# STM32U385xx register map
File version: 1.0
Registers are 32-bit, read-write, reset 0x0 unless marked. A register's access mark holds for its fields unless they carry their own. Offsets are from the block's base; [hi:lo] are bit positions; {n}, {i} and the like mark numbered series; 'fields as' and 'values as' point back to an identical list.

## ICACHE — Instruction Cache
Base 0x40030400
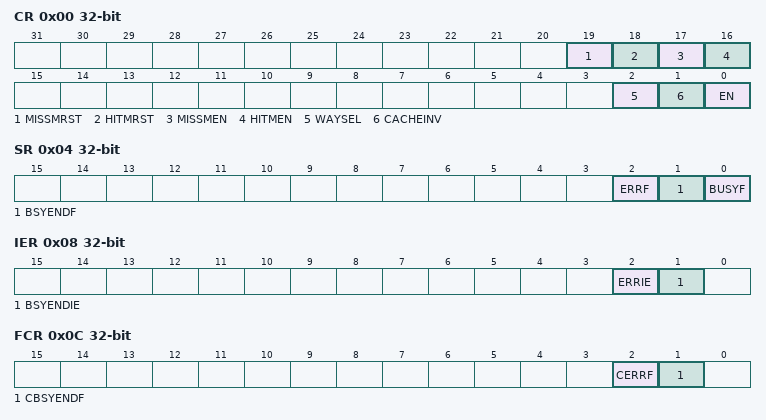
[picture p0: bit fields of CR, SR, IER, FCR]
0x00 CR — ICACHE control register
  [19] MISSMRST — Miss monitor reset
  [18] HITMRST — Hit monitor reset
  [17] MISSMEN — Miss monitor enable
  [16] HITMEN — Hit monitor enable
  [2] WAYSEL — Ways selection
    0=ICACHE_1WAY (1-way cache (direct mapped cache)); 1=ICACHE_2WAYS (2-ways set associative cache (default))
  [1] CACHEINV — Cache invalidation
  [0] EN — Enable
0x04 SR — ICACHE status register
  [2] ERRF — Cache error flag
  [1] BSYENDF — Busy end flag
  [0] BUSYF — Busy flag
0x08 IER — ICACHE interrupt enable register
  [2] ERRIE — Cache error interrupt enable
  [1] BSYENDIE — Busy end interrupt enable
0x0C FCR — ICACHE Flag clear register
  [2] CERRF — Cache error flag clear
  [1] CBSYENDF — Busy end flag clear
0x10 HMONR — ICACHE hit monitor register
  [31:0] HITMON — Cache hit monitor register
0x14 MMONR — ICACHE miss monitor register
  [15:0] MISSMON — Cache miss monitor register
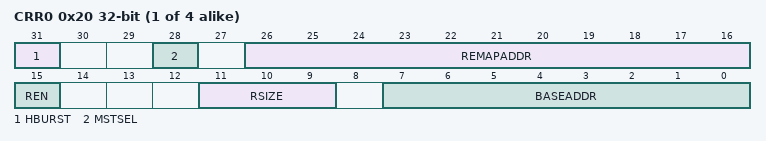
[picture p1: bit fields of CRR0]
{0x20+4i} CRR{i} (i=0..3) — ICACHE region {i} configuration register
  [31] HBURST — Region X output burst type
  [28] MSTSEL — Region X AHB cache master selection
  [26:16] REMAPADDR — Remap address of Region X to be remapped
  [15] REN — Region X enable
  [11:9] RSIZE — Region X size
  [7:0] BASEADDR — Base address of region X to remap

## EXTI — Asynch Interrupt/Event Controller (EXTI)
Base 0x40032000
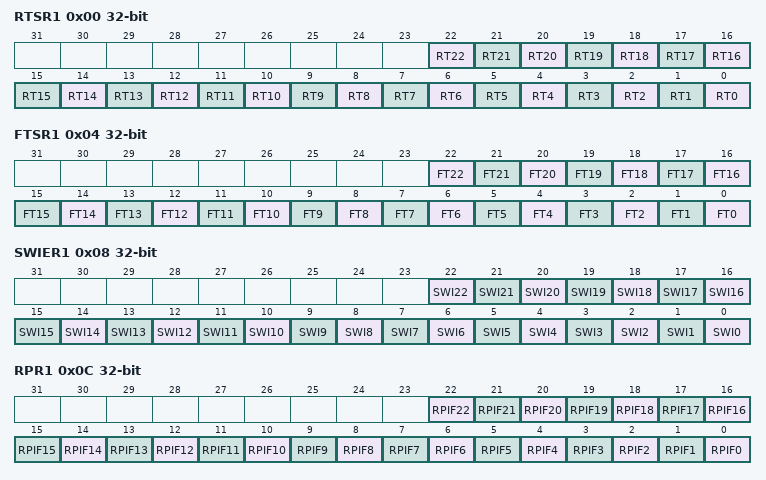
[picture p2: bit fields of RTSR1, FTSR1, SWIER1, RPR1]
0x00 RTSR1 — EXTI Rising Trigger Selection Register 1
  [n] RT{n} (n=0..22) — Rising trigger configuration for input line {n}
0x04 FTSR1 — EXTI Falling Trigger Selection Register 1
  [n] FT{n} (n=0..22) — Falling trigger configuration for input line {n}
0x08 SWIER1 — EXTI Software Interrupt event Register 1
  [n] SWI{n} (n=0..22) — Software Interrupt on line {n}
0x0C RPR1 — EXTI Rising Pending Register 1
  [n] RPIF{n} (n=0..22) — Rising Pending Interrupt Flag on line {n}
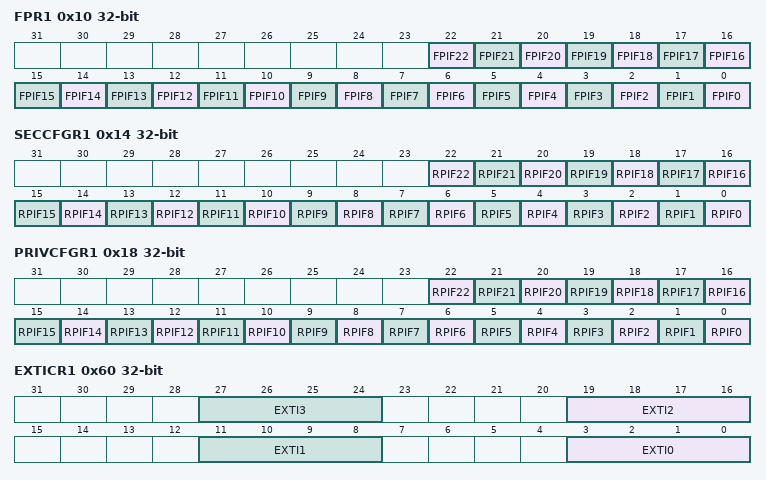
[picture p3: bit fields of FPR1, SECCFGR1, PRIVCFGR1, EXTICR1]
0x10 FPR1 — EXTI Falling Pending Register 1
  [n] FPIF{n} (n=0..22) — Falling Pending Interrupt Flag on line {n}
0x14 SECCFGR1 — EXTI Security Configuration Register 1
  [n] RPIF{n} (n=0..22) — Security enable on line {n}
0x18 PRIVCFGR1 — EXTI Privilege Configuration Register 1
  [n] RPIF{n} (n=0..22) — Privilege enable on line {n}
0x60 EXTICR1 — EXIT External Interrupt Configuration Register, 0x60 -- 0x6C
  [8n+3:8n] EXTI{n} (n=0..3) — EXTI {n} configuration
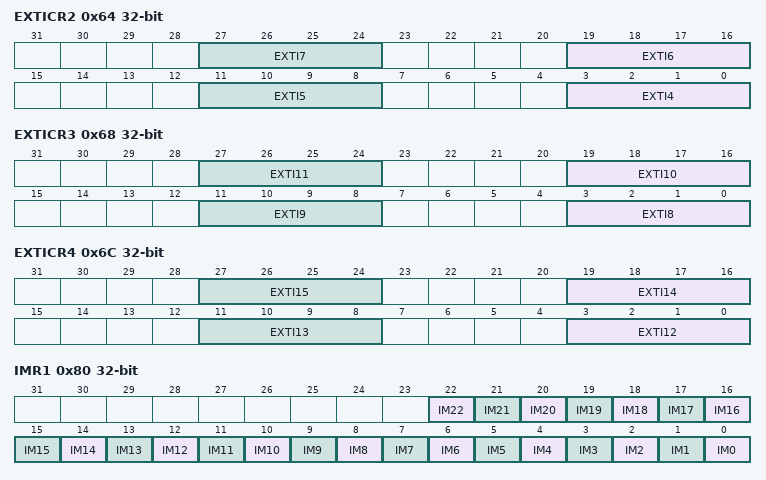
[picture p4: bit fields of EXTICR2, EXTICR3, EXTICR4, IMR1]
0x64 EXTICR2 — EXIT External Interrupt Configuration Register, 0x60 -- 0x6C
  [8n-29:8n-32] EXTI{n} (n=4..7) — EXTI {n} configuration
0x68 EXTICR3 — EXIT External Interrupt Configuration Register, 0x60 -- 0x6C
  [8n-61:8n-64] EXTI{n} (n=8..11) — EXTI {n} configuration
0x6C EXTICR4 — EXIT External Interrupt Configuration Register, 0x60 -- 0x6C
  [8n-93:8n-96] EXTI{n} (n=12..15) — EXTI {n} configuration
0x70 LOCKR — EXTI Lock Register
  [0] LOCK
0x80 IMR1 — EXTI Interrupt Mask Register 1
  [n] IM{n} (n=0..22) — Interrupt Mask on line {n}
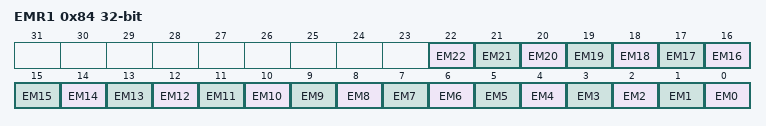
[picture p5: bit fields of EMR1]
0x84 EMR1 — EXTI Event Mask Register 1
  [n] EM{n} (n=0..22) — Event Mask on line {n}

## GTZC_TZSC1 — Global TrustZone Controller
Base 0x40032400
0x00 CR — TZSC control register
  [0] LCK
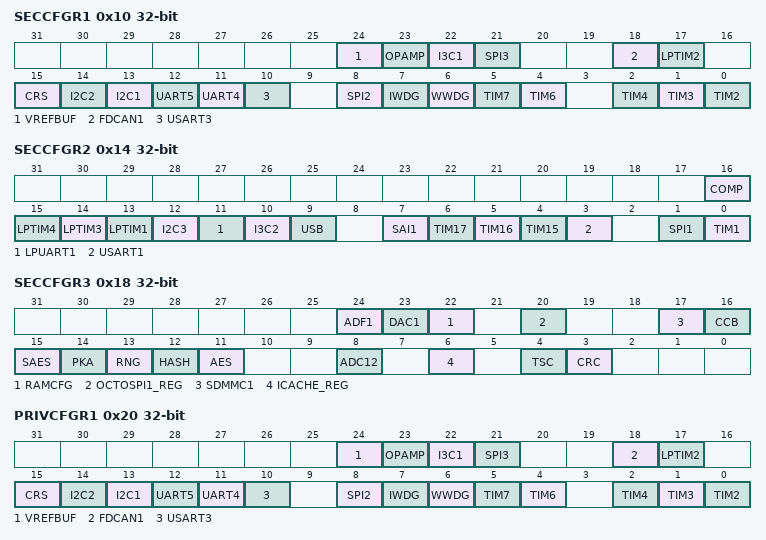
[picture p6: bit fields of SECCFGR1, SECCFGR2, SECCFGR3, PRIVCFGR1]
0x10 SECCFGR1 — TZSC secure configuration register 1
  [24] VREFBUF, [23] OPAMP, [22] I3C1, [21] SPI3, [18] FDCAN1, [17] LPTIM2, [15] CRS, [14] I2C2, [13] I2C1, [12] UART5, [11] UART4, [10] USART3, [8] SPI2, [7] IWDG, [6] WWDG, [5] TIM7, [4] TIM6, [2] TIM4, [1] TIM3, [0] TIM2
0x14 SECCFGR2 — TZSC secure configuration register 2
  [16] COMP, [15] LPTIM4, [14] LPTIM3, [13] LPTIM1, [12] I2C3, [11] LPUART1, [10] I3C2, [9] USB, [7] SAI1, [6] TIM17, [5] TIM16, [4] TIM15, [3] USART1, [1] SPI1, [0] TIM1
0x18 SECCFGR3 — TZSC secure configuration register 3
  [24] ADF1, [23] DAC1, [22] RAMCFG, [20] OCTOSPI1_REG, [17] SDMMC1, [16] CCB, [15] SAES, [14] PKA, [13] RNG, [12] HASH, [11] AES, [8] ADC12, [6] ICACHE_REG, [4] TSC, [3] CRC
0x20 PRIVCFGR1 — TZSC privilege configuration register 1
  fields as SECCFGR1
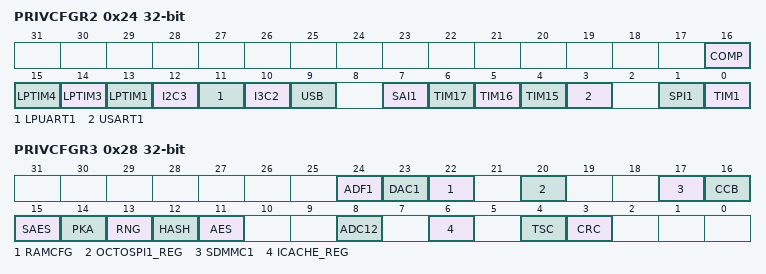
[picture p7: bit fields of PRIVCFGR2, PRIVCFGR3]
0x24 PRIVCFGR2 — TZSC privilege configuration register 2
  fields as SECCFGR2
0x28 PRIVCFGR3 — TZSC privilege configuration register 3
  fields as SECCFGR3
